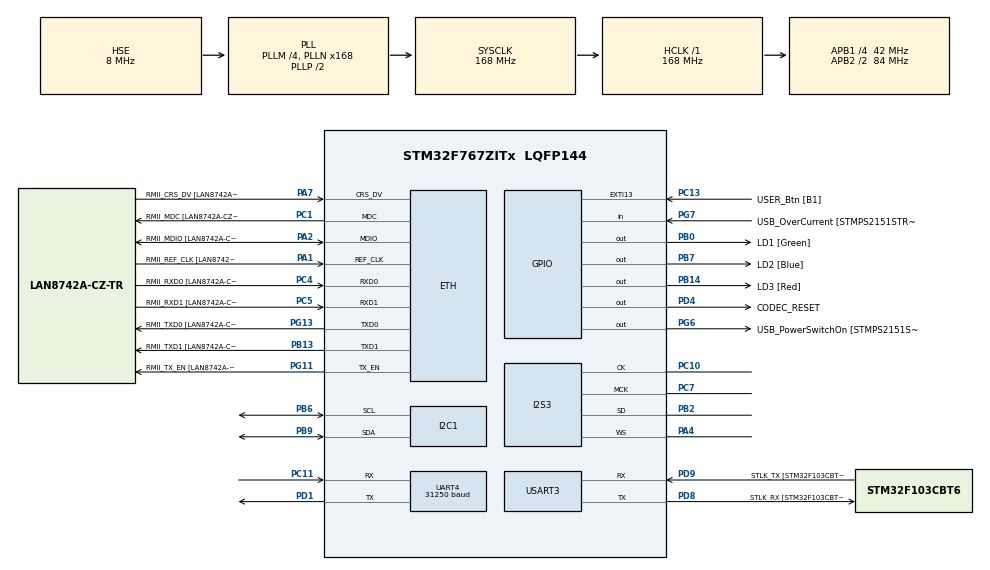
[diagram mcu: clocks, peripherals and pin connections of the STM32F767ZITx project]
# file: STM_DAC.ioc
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Dma.Request0=SPI3_TX
Dma.SPI3_TX.0.Direction=DMA_MEMORY_TO_PERIPH
Dma.SPI3_TX.0.FIFOMode=DMA_FIFOMODE_DISABLE
Dma.SPI3_TX.0.Instance=DMA1_Stream5
Dma.SPI3_TX.0.MemDataAlignment=DMA_MDATAALIGN_HALFWORD
Dma.SPI3_TX.0.MemInc=DMA_MINC_ENABLE
Dma.SPI3_TX.0.Mode=DMA_CIRCULAR
Dma.SPI3_TX.0.PeriphDataAlignment=DMA_PDATAALIGN_HALFWORD
Dma.SPI3_TX.0.PeriphInc=DMA_PINC_DISABLE
Dma.SPI3_TX.0.Priority=DMA_PRIORITY_HIGH
ETH.MediaInterface=ETH_MEDIA_INTERFACE_RMII
ETH.PHY_Name=LAN8742A_PHY_ADDRESS
ETH.PHY_Value=0
ETH.PhyAddress=0
I2C1.Timing=0x00A0A3F7
I2S3.AudioFreq=I2S_AUDIOFREQ_48K
I2S3.ErrorAudioFreq=-2.34 %
I2S3.FullDuplexMode=I2S_FULLDUPLEXMODE_DISABLE
I2S3.Instance=SPI$Index
I2S3.RealAudioFreq=46.875 KHz
I2S3.VirtualMode=I2S_MODE_MASTER
Mcu.Family=STM32F7
Mcu.Name=STM32F767ZITx
Mcu.Package=LQFP144
NVIC.DMA1_Stream5_IRQn=true\:0\:0\:false\:false\:true\:false\:true
NVIC.PriorityGroup=NVIC_PRIORITYGROUP_4
PA1.GPIO_Label=RMII_REF_CLK [LAN8742A-CZ-TR_REFCLK0]
PA1.Mode=RMII
PA1.Signal=ETH_REF_CLK
PA10.GPIO_Label=USB_ID
PA10.Signal=USB_OTG_FS_ID
PA11.GPIO_Label=USB_DM
PA11.Signal=USB_OTG_FS_DM
PA12.GPIO_Label=USB_DP
PA12.Signal=USB_OTG_FS_DP
PA13.GPIO_Label=TMS
PA13.Mode=Serial_Wire
PA13.Signal=SYS_JTMS-SWDIO
PA14.GPIO_Label=TCK
PA14.Mode=Serial_Wire
PA14.Signal=SYS_JTCK-SWCLK
PA2.GPIO_Label=RMII_MDIO [LAN8742A-CZ-TR_MDIO]
PA2.Mode=RMII
PA2.Signal=ETH_MDIO
PA4.Mode=Half_Duplex_Master
PA4.Signal=I2S3_WS
PA7.GPIO_Label=RMII_CRS_DV [LAN8742A-CZ-TR_CRS_DV]
PA7.Mode=RMII
PA7.Signal=ETH_CRS_DV
PA8.GPIO_Label=USB_SOF [TP1]
PA8.Signal=USB_OTG_FS_SOF
PA9.GPIO_Label=USB_VBUS
PA9.Signal=USB_OTG_FS_VBUS
PB0.GPIO_Label=LD1 [Green]
PB0.Signal=GPIO_Output
PB13.GPIO_Label=RMII_TXD1 [LAN8742A-CZ-TR_TXD1]
PB13.Mode=RMII
PB13.Signal=ETH_TXD1
PB14.GPIO_Label=LD3 [Red]
PB14.Signal=GPIO_Output
PB2.Mode=Half_Duplex_Master
PB2.Signal=I2S3_SD
PB3.GPIO_Label=SWO
PB3.Signal=SYS_JTDO-SWO
PB6.Mode=I2C
PB6.Signal=I2C1_SCL
PB7.GPIO_Label=LD2 [Blue]
PB7.Signal=GPIO_Output
PB9.Mode=I2C
PB9.Signal=I2C1_SDA
PC1.GPIO_Label=RMII_MDC [LAN8742A-CZ-TR_MDC]
PC1.Mode=RMII
PC1.Signal=ETH_MDC
PC10.Mode=Half_Duplex_Master
PC10.Signal=I2S3_CK
PC11.Mode=Asynchronous
PC11.Signal=UART4_RX
PC13.GPIO_Label=USER_Btn [B1]
PC13.Signal=GPXTI13
PC14/OSC32_IN.Signal=RCC_OSC32_IN
PC15/OSC32_OUT.Signal=RCC_OSC32_OUT
PC4.GPIO_Label=RMII_RXD0 [LAN8742A-CZ-TR_RXD0]
PC4.Mode=RMII
PC4.Signal=ETH_RXD0
PC5.GPIO_Label=RMII_RXD1 [LAN8742A-CZ-TR_RXD1]
PC5.Mode=RMII
PC5.Signal=ETH_RXD1
PC7.Mode=Master_Clock_Activated
PC7.Signal=I2S3_MCK
PD1.Mode=Asynchronous
PD1.Signal=UART4_TX
PD4.GPIO_Label=CODEC_RESET
PD4.Signal=GPIO_Output
PD8.GPIO_Label=STLK_RX [STM32F103CBT6_PA3]
PD8.Mode=Asynchronous
PD8.Signal=USART3_TX
PD9.GPIO_Label=STLK_TX [STM32F103CBT6_PA2]
PD9.Mode=Asynchronous
PD9.Signal=USART3_RX
PG11.GPIO_Label=RMII_TX_EN [LAN8742A-CZ-TR_TXEN]
PG11.Mode=RMII
PG11.Signal=ETH_TX_EN
PG13.GPIO_Label=RMII_TXD0 [LAN8742A-CZ-TR_TXD0]
PG13.Mode=RMII
PG13.Signal=ETH_TXD0
PG6.GPIO_Label=USB_PowerSwitchOn [STMPS2151STR_EN]
PG6.Signal=GPIO_Output
PG7.GPIO_Label=USB_OverCurrent [STMPS2151STR_FAULT]
PG7.Signal=GPIO_Input
PH0/OSC_IN.GPIO_Label=MCO [STM32F103CBT6_PA8]
PH0/OSC_IN.Mode=HSE-External-Oscillator
PH0/OSC_IN.Signal=RCC_OSC_IN
PH1/OSC_OUT.Mode=HSE-External-Oscillator
PH1/OSC_OUT.Signal=RCC_OSC_OUT
ProjectManager.HeapSize=0x200
ProjectManager.StackSize=0x400
ProjectManager.TargetToolchain=STM32CubeIDE
RCC.48MHZClocksFreq_Value=24000000
RCC.AHBFreq_Value=168000000
RCC.APB1CLKDivider=RCC_HCLK_DIV4
RCC.APB1Freq_Value=42000000
RCC.APB1TimFreq_Value=84000000
RCC.APB2CLKDivider=RCC_HCLK_DIV2
RCC.APB2Freq_Value=84000000
RCC.APB2TimFreq_Value=168000000
RCC.CortexFreq_Value=168000000
RCC.HCLKFreq_Value=168000000
RCC.HSE_VALUE=8000000
RCC.HSI_VALUE=16000000
RCC.LSE_VALUE=32768
RCC.PLLI2SN=96
RCC.PLLM=4
RCC.PLLMUL=RCC_PLL_MUL9
RCC.PLLN=168
RCC.PLLQ=7
RCC.PLLSourceVirtual=RCC_PLLSOURCE_HSE
RCC.PRESCALERUSB=RCC_USBCLKSOURCE_PLL_DIV1_5
RCC.SYSCLKFreq_VALUE=168000000
RCC.SYSCLKSource=RCC_SYSCLKSOURCE_PLLCLK
RCC.SYSCLKSourceVirtual=RCC_SYSCLKSOURCE_PLLCLK
RCC.USBFreq_Value=48000000
RCC.VCOOutputFreq_Value=336000000
UART4.BaudRate=31250
USART3.VirtualMode-Asynchronous=VM_ASYNC
board=NUCLEO-F767ZI

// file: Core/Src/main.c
/* USER CODE BEGIN Header */
/**
  ******************************************************************************
  * @file           : main.c
  * @brief          : Main program body
  ******************************************************************************
  * @attention
  *
  * <h2><center>&copy; Copyright (c) 2021 STMicroelectronics.
  * All rights reserved.</center></h2>
  *
  * This software component is licensed by ST under BSD 3-Clause license,
  * the "License"; You may not use this file except in compliance with the
  * License. You may obtain a copy of the License at:
  *                        opensource.org/licenses/BSD-3-Clause
  *
  ******************************************************************************
  */
/* USER CODE END Header */
#include "main.h"

ETH_HandleTypeDef heth;

I2C_HandleTypeDef hi2c1;

I2S_HandleTypeDef hi2s3;
DMA_HandleTypeDef hdma_spi3_tx;

UART_HandleTypeDef huart4;
UART_HandleTypeDef huart3;

PCD_HandleTypeDef hpcd_USB_OTG_FS;

void SystemClock_Config(void);
static void MX_GPIO_Init(void);
static void MX_ETH_Init(void);
static void MX_USART3_UART_Init(void);
static void MX_DMA_Init(void);
static void MX_USB_OTG_FS_PCD_Init(void);
static void MX_I2C1_Init(void);
static void MX_I2S3_Init(void);
static void MX_UART4_Init(void);

int main(void)
{

  /* MCU Configuration--------------------------------------------------------*/

  /* Reset of all peripherals, Initializes the Flash interface and the Systick. */
  HAL_Init();

  /* Configure the system clock */
  SystemClock_Config();

  /* Initialize all configured peripherals */
  MX_GPIO_Init();
  MX_ETH_Init();
  MX_USART3_UART_Init();
  MX_DMA_Init();
  MX_USB_OTG_FS_PCD_Init();
  MX_I2C1_Init();
  MX_I2S3_Init();
  MX_UART4_Init();

  /* Infinite loop */
  while (1)
  {

  }
}

void SystemClock_Config(void)
{
  RCC_OscInitTypeDef RCC_OscInitStruct = {0};
  RCC_ClkInitTypeDef RCC_ClkInitStruct = {0};
  RCC_PeriphCLKInitTypeDef PeriphClkInitStruct = {0};

  /** Configure the main internal regulator output voltage
  */
  __HAL_RCC_PWR_CLK_ENABLE();
  __HAL_PWR_VOLTAGESCALING_CONFIG(PWR_REGULATOR_VOLTAGE_SCALE2);
  /** Initializes the RCC Oscillators according to the specified parameters
  * in the RCC_OscInitTypeDef structure.
  */
  RCC_OscInitStruct.OscillatorType = RCC_OSCILLATORTYPE_HSE;
  RCC_OscInitStruct.HSEState = RCC_HSE_ON;
  RCC_OscInitStruct.PLL.PLLState = RCC_PLL_ON;
  RCC_OscInitStruct.PLL.PLLSource = RCC_PLLSOURCE_HSE;
  RCC_OscInitStruct.PLL.PLLM = 4;
  RCC_OscInitStruct.PLL.PLLN = 168;
  RCC_OscInitStruct.PLL.PLLP = RCC_PLLP_DIV2;
  RCC_OscInitStruct.PLL.PLLQ = 7;
  RCC_OscInitStruct.PLL.PLLR = 2;
  if (HAL_RCC_OscConfig(&RCC_OscInitStruct) != HAL_OK)
  {
    Error_Handler();
  }
  /** Initializes the CPU, AHB and APB buses clocks
  */
  RCC_ClkInitStruct.ClockType = RCC_CLOCKTYPE_HCLK|RCC_CLOCKTYPE_SYSCLK
                              |RCC_CLOCKTYPE_PCLK1|RCC_CLOCKTYPE_PCLK2;
  RCC_ClkInitStruct.SYSCLKSource = RCC_SYSCLKSOURCE_PLLCLK;
  RCC_ClkInitStruct.AHBCLKDivider = RCC_SYSCLK_DIV1;
  RCC_ClkInitStruct.APB1CLKDivider = RCC_HCLK_DIV4;
  RCC_ClkInitStruct.APB2CLKDivider = RCC_HCLK_DIV2;

  if (HAL_RCC_ClockConfig(&RCC_ClkInitStruct, FLASH_LATENCY_5) != HAL_OK)
  {
    Error_Handler();
  }
  PeriphClkInitStruct.PeriphClockSelection = RCC_PERIPHCLK_USART3|RCC_PERIPHCLK_UART4
                              |RCC_PERIPHCLK_I2C1|RCC_PERIPHCLK_I2S
                              |RCC_PERIPHCLK_CLK48;
  PeriphClkInitStruct.PLLI2S.PLLI2SN = 96;
  PeriphClkInitStruct.PLLI2S.PLLI2SP = RCC_PLLP_DIV2;
  PeriphClkInitStruct.PLLI2S.PLLI2SR = 2;
  PeriphClkInitStruct.PLLI2S.PLLI2SQ = 2;
  PeriphClkInitStruct.PLLI2SDivQ = 1;
  PeriphClkInitStruct.I2sClockSelection = RCC_I2SCLKSOURCE_PLLI2S;
  PeriphClkInitStruct.Usart3ClockSelection = RCC_USART3CLKSOURCE_PCLK1;
  PeriphClkInitStruct.Uart4ClockSelection = RCC_UART4CLKSOURCE_PCLK1;
  PeriphClkInitStruct.I2c1ClockSelection = RCC_I2C1CLKSOURCE_PCLK1;
  PeriphClkInitStruct.Clk48ClockSelection = RCC_CLK48SOURCE_PLL;
  if (HAL_RCCEx_PeriphCLKConfig(&PeriphClkInitStruct) != HAL_OK)
  {
    Error_Handler();
  }
}

static void MX_ETH_Init(void)
{

   static uint8_t MACAddr[6];

  heth.Instance = ETH;
  heth.Init.AutoNegotiation = ETH_AUTONEGOTIATION_ENABLE;
  heth.Init.Speed = ETH_SPEED_100M;
  heth.Init.DuplexMode = ETH_MODE_FULLDUPLEX;
  heth.Init.PhyAddress = LAN8742A_PHY_ADDRESS;
  MACAddr[0] = 0x00;
  MACAddr[1] = 0x80;
  MACAddr[2] = 0xE1;
  MACAddr[3] = 0x00;
  MACAddr[4] = 0x00;
  MACAddr[5] = 0x00;
  heth.Init.MACAddr = &MACAddr[0];
  heth.Init.RxMode = ETH_RXPOLLING_MODE;
  heth.Init.ChecksumMode = ETH_CHECKSUM_BY_HARDWARE;
  heth.Init.MediaInterface = ETH_MEDIA_INTERFACE_RMII;

  if (HAL_ETH_Init(&heth) != HAL_OK)
  {
    Error_Handler();
  }

}

static void MX_I2C1_Init(void)
{

  hi2c1.Instance = I2C1;
  hi2c1.Init.Timing = 0x00A0A3F7;
  hi2c1.Init.OwnAddress1 = 0;
  hi2c1.Init.AddressingMode = I2C_ADDRESSINGMODE_7BIT;
  hi2c1.Init.DualAddressMode = I2C_DUALADDRESS_DISABLE;
  hi2c1.Init.OwnAddress2 = 0;
  hi2c1.Init.OwnAddress2Masks = I2C_OA2_NOMASK;
  hi2c1.Init.GeneralCallMode = I2C_GENERALCALL_DISABLE;
  hi2c1.Init.NoStretchMode = I2C_NOSTRETCH_DISABLE;
  if (HAL_I2C_Init(&hi2c1) != HAL_OK)
  {
    Error_Handler();
  }
  /** Configure Analogue filter
  */
  if (HAL_I2CEx_ConfigAnalogFilter(&hi2c1, I2C_ANALOGFILTER_ENABLE) != HAL_OK)
  {
    Error_Handler();
  }
  /** Configure Digital filter
  */
  if (HAL_I2CEx_ConfigDigitalFilter(&hi2c1, 0) != HAL_OK)
  {
    Error_Handler();
  }

}

static void MX_I2S3_Init(void)
{

  hi2s3.Instance = SPI3;
  hi2s3.Init.Mode = I2S_MODE_MASTER_TX;
  hi2s3.Init.Standard = I2S_STANDARD_PHILIPS;
  hi2s3.Init.DataFormat = I2S_DATAFORMAT_16B;
  hi2s3.Init.MCLKOutput = I2S_MCLKOUTPUT_ENABLE;
  hi2s3.Init.AudioFreq = I2S_AUDIOFREQ_48K;
  hi2s3.Init.CPOL = I2S_CPOL_LOW;
  hi2s3.Init.ClockSource = I2S_CLOCK_PLL;
  if (HAL_I2S_Init(&hi2s3) != HAL_OK)
  {
    Error_Handler();
  }

}

static void MX_UART4_Init(void)
{

  huart4.Instance = UART4;
  huart4.Init.BaudRate = 31250 ;
  huart4.Init.WordLength = UART_WORDLENGTH_8B;
  huart4.Init.StopBits = UART_STOPBITS_1;
  huart4.Init.Parity = UART_PARITY_NONE;
  huart4.Init.Mode = UART_MODE_TX_RX;
  huart4.Init.HwFlowCtl = UART_HWCONTROL_NONE;
  huart4.Init.OverSampling = UART_OVERSAMPLING_16;
  huart4.Init.OneBitSampling = UART_ONE_BIT_SAMPLE_DISABLE;
  huart4.AdvancedInit.AdvFeatureInit = UART_ADVFEATURE_NO_INIT;
  if (HAL_UART_Init(&huart4) != HAL_OK)
  {
    Error_Handler();
  }

}

static void MX_USART3_UART_Init(void)
{

  huart3.Instance = USART3;
  huart3.Init.BaudRate = 115200;
  huart3.Init.WordLength = UART_WORDLENGTH_8B;
  huart3.Init.StopBits = UART_STOPBITS_1;
  huart3.Init.Parity = UART_PARITY_NONE;
  huart3.Init.Mode = UART_MODE_TX_RX;
  huart3.Init.HwFlowCtl = UART_HWCONTROL_NONE;
  huart3.Init.OverSampling = UART_OVERSAMPLING_16;
  huart3.Init.OneBitSampling = UART_ONE_BIT_SAMPLE_DISABLE;
  huart3.AdvancedInit.AdvFeatureInit = UART_ADVFEATURE_NO_INIT;
  if (HAL_UART_Init(&huart3) != HAL_OK)
  {
    Error_Handler();
  }

}

static void MX_USB_OTG_FS_PCD_Init(void)
{

  hpcd_USB_OTG_FS.Instance = USB_OTG_FS;
  hpcd_USB_OTG_FS.Init.dev_endpoints = 6;
  hpcd_USB_OTG_FS.Init.speed = PCD_SPEED_FULL;
  hpcd_USB_OTG_FS.Init.dma_enable = DISABLE;
  hpcd_USB_OTG_FS.Init.phy_itface = PCD_PHY_EMBEDDED;
  hpcd_USB_OTG_FS.Init.Sof_enable = ENABLE;
  hpcd_USB_OTG_FS.Init.low_power_enable = DISABLE;
  hpcd_USB_OTG_FS.Init.lpm_enable = DISABLE;
  hpcd_USB_OTG_FS.Init.vbus_sensing_enable = ENABLE;
  hpcd_USB_OTG_FS.Init.use_dedicated_ep1 = DISABLE;
  if (HAL_PCD_Init(&hpcd_USB_OTG_FS) != HAL_OK)
  {
    Error_Handler();
  }

}

static void MX_DMA_Init(void)
{

  /* DMA controller clock enable */
  __HAL_RCC_DMA1_CLK_ENABLE();

  /* DMA interrupt init */
  /* DMA1_Stream5_IRQn interrupt configuration */
  HAL_NVIC_SetPriority(DMA1_Stream5_IRQn, 0, 0);
  HAL_NVIC_EnableIRQ(DMA1_Stream5_IRQn);
  HAL_UART_IRQHandler(UART4);
}

static void MX_GPIO_Init(void)
{
  GPIO_InitTypeDef GPIO_InitStruct = {0};

  /* GPIO Ports Clock Enable */
  __HAL_RCC_GPIOC_CLK_ENABLE();
  __HAL_RCC_GPIOH_CLK_ENABLE();
  __HAL_RCC_GPIOA_CLK_ENABLE();
  __HAL_RCC_GPIOB_CLK_ENABLE();
  __HAL_RCC_GPIOD_CLK_ENABLE();
  __HAL_RCC_GPIOG_CLK_ENABLE();

  /*Configure GPIO pin Output Level */
  HAL_GPIO_WritePin(GPIOB, LD1_Pin|LD3_Pin|LD2_Pin, GPIO_PIN_RESET);

  /*Configure GPIO pin Output Level */
  HAL_GPIO_WritePin(USB_PowerSwitchOn_GPIO_Port, USB_PowerSwitchOn_Pin, GPIO_PIN_RESET);

  /*Configure GPIO pin Output Level */
  HAL_GPIO_WritePin(CODEC_RESET_GPIO_Port, CODEC_RESET_Pin, GPIO_PIN_RESET);

  /*Configure GPIO pin : USER_Btn_Pin */
  GPIO_InitStruct.Pin = USER_Btn_Pin;
  GPIO_InitStruct.Mode = GPIO_MODE_IT_RISING;
  GPIO_InitStruct.Pull = GPIO_NOPULL;
  HAL_GPIO_Init(USER_Btn_GPIO_Port, &GPIO_InitStruct);

  /*Configure GPIO pins : LD1_Pin LD3_Pin LD2_Pin */
  GPIO_InitStruct.Pin = LD1_Pin|LD3_Pin|LD2_Pin;
  GPIO_InitStruct.Mode = GPIO_MODE_OUTPUT_PP;
  GPIO_InitStruct.Pull = GPIO_NOPULL;
  GPIO_InitStruct.Speed = GPIO_SPEED_FREQ_LOW;
  HAL_GPIO_Init(GPIOB, &GPIO_InitStruct);

  /*Configure GPIO pin : USB_PowerSwitchOn_Pin */
  GPIO_InitStruct.Pin = USB_PowerSwitchOn_Pin;
  GPIO_InitStruct.Mode = GPIO_MODE_OUTPUT_PP;
  GPIO_InitStruct.Pull = GPIO_NOPULL;
  GPIO_InitStruct.Speed = GPIO_SPEED_FREQ_LOW;
  HAL_GPIO_Init(USB_PowerSwitchOn_GPIO_Port, &GPIO_InitStruct);

  /*Configure GPIO pin : USB_OverCurrent_Pin */
  GPIO_InitStruct.Pin = USB_OverCurrent_Pin;
  GPIO_InitStruct.Mode = GPIO_MODE_INPUT;
  GPIO_InitStruct.Pull = GPIO_NOPULL;
  HAL_GPIO_Init(USB_OverCurrent_GPIO_Port, &GPIO_InitStruct);

  /*Configure GPIO pin : CODEC_RESET_Pin */
  GPIO_InitStruct.Pin = CODEC_RESET_Pin;
  GPIO_InitStruct.Mode = GPIO_MODE_OUTPUT_PP;
  GPIO_InitStruct.Pull = GPIO_NOPULL;
  GPIO_InitStruct.Speed = GPIO_SPEED_FREQ_LOW;
  HAL_GPIO_Init(CODEC_RESET_GPIO_Port, &GPIO_InitStruct);

}

void StartDefaultTask(void const * argument)
{
  /* USER CODE BEGIN 5 */
  /* Infinite loop */
	  cpp_link();
	  // NEVER GETS HERE, cpp_link goes to application init and then loop
  for(;;)
  {
    osDelay(10000);
  }
  /* USER CODE END 5 */
}

void Error_Handler(void)
{
  __disable_irq();
  while (1)
  {
  }
}

/************************ (C) COPYRIGHT STMicroelectronics *****END OF FILE****/
